# RL6955_IP_SVD register map
Vendor: Realtek
Registers are 32-bit, read-write, reset 0x0 unless marked. A register's access mark holds for its fields unless they carry their own. Offsets are from the block's base; [hi:lo] are bit positions; lines under a group give offsets from that group; {n}, {i} and the like mark numbered series; <NAME> marks a mode.

## PSRAM_REG (part 1 of 2)
Base 0x41909000
Same registers: SPI_FLASH_CTRL 0x4190B000
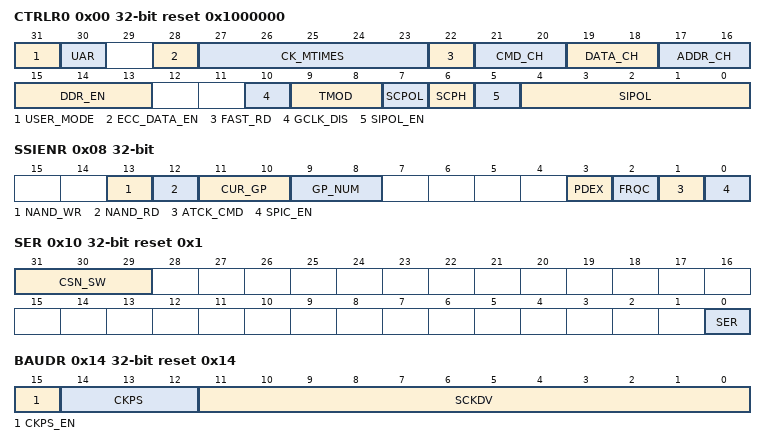
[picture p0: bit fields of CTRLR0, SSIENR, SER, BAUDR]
0x00 CTRLR0 reset 0x1000000 — Control Register 0
  [31] USER_MODE — User mode bit. Enable to enter user mode. Disable to enter auto mode. It can not be changed while SPIC is busy (28 [0] BUSY). 1: User mode. User can push data to FIFO and set SSIENR to 1. SPIC won't accept auto read/write command. 0: Auto mode. User can't push data to FIFO and set SSIENR to 1. SPIC will accept auto read/write command.
  [30] UAR — User mode bit auto reset. Enable to auto reset USER_MODE to 0 after current user mode transaction is over (SPIC_EN reset to 0).
  [28] ECC_DATA_EN — Indicate the data path should go through ECC in NAND user mode read write. ECC mode. User should program 0x170 and 0x174. The read/write data flow will go through ECC module. Normal mode. The read/write data flow will bypass ECC module. Exists: TAG >= 2.0.11. Available only if configuration of NAND_EN and ECC_EN are defined.
  [27:23] CK_MTIMES — Indicates the check times. If Flash is always busy in auto-check times, it causes ACEIR interrupt. The delay time (cycles) is related to bus_clk. The cycles of the parameter = (CK_MTIMES << (11+ATCK_BIT_EXTEND).). User should ensure the timeout > Write time of Flash The timeout time(ns) = 2*BAUDR*(1/SPIC_freq)(8/CH) (CK_MTIMES << (11+ATCK_BIT_EXTEND).) Example 1: Flash Program time= 1ms, BAUDR=1, CH=1 (SPI) and (1/SPIC_freq) = 10ns. ATCK_MTIMES should be to set 4. Example 2: SPIC_freq = 200MHz, BAUDR = 1, CH =4 (QSPI), and ATCK_BIT_EXTEND = 2, the maximum auto_check time should be = 2*1*(1/200MHz)(8/4) (5'b11111<<13) = 2*1*(1/200MHz)(8/4) (18'b11_1110_0000_0000_0000) = 2*1*(1/200MHz)(8/4) (18'h3_e000) = 2*1*(1/200MHz)(8/4) (253952) = 5079040 ns = 5.07 ms Suggestion: If ACEIR interrupt occurs, the user should check the flash status by the software itself. Note: Before SVN 8369 Version, CK_MTIMES is fixed to shift 10bit. The formula becomes 2*BAUDR*(1/SPIC_freq)(8/CH) (CK_MTIMES << (10))
  [22] FAST_RD — Indicates to use fast read command in user mode. If setting to 1, SPIC would use FBAUDR to generate spi_sclk.
  [21:20] CMD_CH — Indicates channel number of command phase in transmitting or receiving data. Command phase is usually used to send SPI command. 0: single channel 1: dual channels 2: quad channels 3: octal channel
  [19:18] DATA_CH — Indicates channel number of data phase in transmitting or receiving data. Data phase is used to send data after address phase. 0: single channel 1: dual channels 2: quad channels 3: octal channel
  [17:16] ADDR_CH — Indicates channel number of address phase after command phase. Addr phase is used to send address or data. Addr phase is between one-byte command and a data phase. The number of bytes is determined by the ADDR_LENGTH. 0: single channel 1: dual channels 2: quad channels 3: octal channel
  [15:13] DDR_EN — Indicates the DDR mode in CMD_CH/DATA_CH/ADDR_CH. CTRLR0[15]: CMD_CH (always 2-Byte CMD type) CTRLR0[14]: DATA_CH CTRLR0[13]: ADDR_CH 0: Disable 1: Enable Available only if configuration of DDR_EN is defined.
  [10] GCLK_DIS — Set to disable gated clock of icg cell
  [9:8] TMOD — Indicates transfer mode. 2'b00: transmit mode Others (or 2'b11): receive mode
  [7] SCPOL — Indicates serial clock polarity. It is used to select the polarity of the inactive serial clock. 0: inactive state of serial clock is low 1: inactive state of serial clock is high
  [6] SCPH — Indicates serial clock phase. The serial clock phase selects the relationship the serial clock with the slave select signal. 0: serial clock toggles in middle of first data bit 1: serial clock toggles at start of first data bit
  [5] SIPOL_EN — Set to enable SIPOL
  [4:0] SIPOL — While SIPOL_EN = 1 : SPI_CS is inactive state (SPI_CS ==1): spi_sin[3:0] = SIPOL[3:0] SPI_CS is active(SPI_CS ==0): spi_sin[3:1] = SIPOL[3:1] (single channel) spi_sin[3:2] = SIPOL[3:2] (dual channel) (SIPOL[4]: reserved for spi_in[7:4])
0x04 RX_NDF — Control Register 1
  [23:0] RX_NDF — Indicates a number of data frames (unit: Byte). When executing receives operation in user mode, SPIC receives data continuously until data frames are equal to RX_NDF.
0x08 SSIENR access per field — SPIC Enable Register
  [13] NAND_WR rw — Set to enable SPIC when start NAND auto command flow in user mode write transactions. To start NAND auto command flow user write transaction, please do not set SSIENR.SPIC_EN. If NAND_WR is activated, SPIC will send WEN command, Page Load program data command and Page execute command to NAND Flash. Write: 0 - Not to activate NAND auto command flow user write 1 - Activate NAND auto command flow user write Read: 0 - NAND auto command flow user write is done 1 - NAND auto command flow user write is still in progress
  [12] NAND_RD rw — Set to enable SPIC when start NAND auto command flow in user read transactions. To start NAND auto command flow user read transaction, please do not set SSIENR.SPIC_EN. If NAND_RD is activated, SPIC will send Page read data command and Read data command to NAND Flash. Write: 0 - Not to activate NAND auto command flow user read 1 - Activate NAND auto command flow user read Read: 0 - NAND auto command flow user read is done 1 - NAND auto command flow user read is still in progress
  [11:10] CUR_GP ro — Only used in frequency change function. Used to identify which group register data is internal used. When frqc_req and frqc_ack are both high, CUR_GP will switch to the group which in GP_NUM. Exists: TAG >= 1.0.4.
  [9:8] GP_NUM rw — Only used in frequency change function. Set to determine which group register user want to read or write. Base on different operation frequency, some control register setting will change. Therefore we build second group register on USER_LENGTH.USER_RD_DUMMY_LENGTH, AUTO_LENGTH.RD_DUMMY_LENGTH, AUTO_LENGTH.RDSR_DUMMY_LENGTH, AUTO_LENGTH.IN_PHYSICAL_CYC, TPR0.CS_TCEM, TPR0.CS_ACTIVE_HOLD, TPR0.CS_H_WR_DUM_LEN, TPR0.CS_H_RD_DUM_LEN, AUTO_LENGTH2.WR_DUMMY_LENGTH, TPR1.CR_TPWR, TPR1.CR_IDLE_WINDOW, TPR1.CS_ACTICE_SETUP. Exists: TAG >= 1.0.4.
  [3] PDEX rw — Set to trigger device enter sleep mode or deep power down mode. After setting PDEX_CTRL0, PDEX_CTRL1, PDEX_CTRL2 and TPR2, then set this bit to trigger PDEX flow. Write: 0 - Not to activate PDEX 1 - Activate PDEX Read: 0 - PDEX is still in progress 1 - PDEX is done Exists: TAG >= 2.0.5.
  [2] FRQC rw — Set to enable frequency change function. SPIC will chop current transaction and then set frqc_req = 1 after setting this bit. Frquency change is finished when frqc_req and frqc_ack are both high and then the choped transaction will return and continue. Write: 0: Not to activate FRQC 1: Activate FRQC Read: 0: FRQC is still in progress 1: FRQC is done Exists: TAG >= 1.0.4.
  [1] ATCK_CMD rw — Set to enable ATCK_CMD implementation. After setting SPIC would not accept any command until checking Flash is not busy or checking time out. (Use in User Mode, especially for Erase/Program to check status automatically.) If CTRLR2.SEQ_SET setting, this function needs to disable.
  [0] SPIC_EN rw — Set to enable SPIC and start user mode transaction. SPIC will reset SPIC_EN to 0 after user mode transaction is finished. SPIC_EN can only be set when BOOT_FIN=1 (boot finished) and USER_MODE=1 (user mode). (User can read SPIC_EN to check whether current user mode transaction is finished.)
0x10 SER reset 0x1 — Slave Enable Register
  [31:29] CSN_SW — Set to determine the switch of csn0 and csn1~3. 3'b000: no switch 3'b001: csn0 switch with cs1 3'b010: csn0 switch with cs2 3'b100: csn0 switch with cs3 Exists: TAG >= 2.0.8.
  [0] SER — Each bit in the register corresponds to one SPI Flash. In user mode user program the register to select target flash. 0: Not selected 1: Selected
0x14 BAUDR reset 0x14 — Baud Rate Select
  [15] CKPS_EN — CKPS enable bit. Set this bit to use CKPS feature. Exists: TAG >= 2.0.8.
  [14:12] CKPS — Indicate the shift range of device clk (SCLK) when CKPS_EN is set. (unit: bus_clk) Exists: TAG >= 2.0.8.
  [11:0] SCKDV — Define spi_sclk divider value. The frequency of spi_sclk is derived from: The frequency of spi_sclk = The frequency of bus_clk/(2*SCKDV).
0x18 TXFTLR — Transmit FIFO Threshold level
  [4:0] TFT — Transmit FIFO threshold. To Control FIFO entries of valid data in normal transfer except in receiving mode. When a number of FIFO entry is equal or smaller than TFT, SPIC triggers a spi_txeir interrupt. Ex: If TXFTLR = 5'h1, set spi_txeir when FIFO entries <= TFT (1)
0x1C RXFTLR reset 0x1F — Receive FIFO Threshold level
  [4:0] RFT — Receive FIFO threshold. To Control FIFO entries of valid data in receiving mode. When a number of FIFO entry is greater than RFT, SPIC triggers a spi_rxfir interrupt. Ex: If RXFTLR = 5'h1, set spi_rxfir when FIFO entries > RFT (1)
0x20 TXFLR ro — Transmit FIFO level Register
  [5:0] TXFLR — Transmit FIFO level. Indicates the FIFO entry level of valid data in normal mode except in receiving data. (or as FIFO_FLR in any mode)
0x24 RXFLR ro — Receive FIFO level Register
  [5:0] RXFLR — Receive FIFO level. Indicates the FIFO entries of valid data in receiving data.
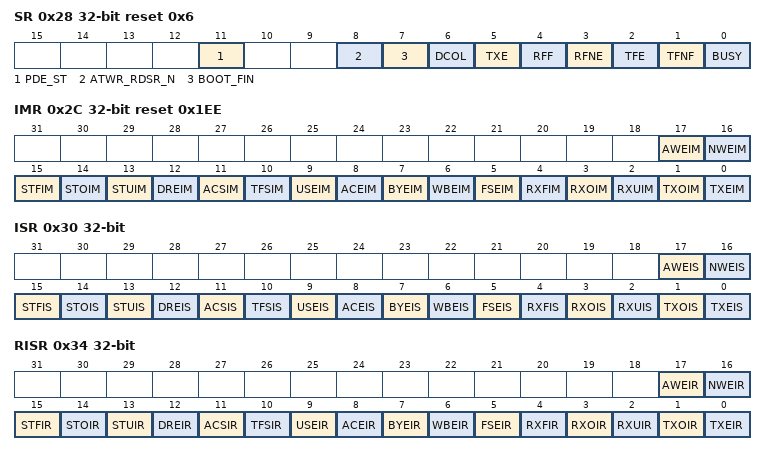
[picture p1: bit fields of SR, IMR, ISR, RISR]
0x28 SR access per field reset 0x6 — Status Register
  [11] PDE_ST ro — PDE state. Set if device has entered DPD/Sleep Mode Exists: TAG >= 2.0.7. Available only if configuration of SPI_PDEX_ENABLE is defined.
  [8] ATWR_RDSR_N rw — The previous auto write cmd didn't check the status register (RDSR). User should check the status register of Flash before next user mode transaction.
  [7] BOOT_FIN ro — Boot Finish. Set if count waiting cycles (Boot Delay Count) for SPI Flash becomes a stable state after power on (or system reset). 1: Boot Finish Note: Auto_mode would be blocked until boot finish. User cannot set CR until boot finish.
  [6] DCOL ro — Data Collision, or in Transmitting Status. 1: Status shows that SPIC is transmitting spi_flash_cmd/spi_flash_addr/spi_flash_data to SPI Flash. Suggest not reading DR during this transmitting state. (Check this status can avoid reading wrong data and cause SPIC error.)
  [5] TXE ro — Transmission error. Set if FIFO is empty and starting to transmit data to SPI Flash. This bit is cleared when read.
  [4] RFF ro — Receive FIFO full. Set if FIFO is full in receiving mode. This bit is cleared when read.
  [3] RFNE ro — Receive FIFO is not empty. Set if FIFO is not empty in receiving mode. This bit is cleared when read.
  [2] TFE ro — Transmit FIFO is empty. Set if FIFO is empty in transmit mode, else it is cleared when it has data in FIFO.
  [1] TFNF ro — Transmit FIFO is not full. Set if FIFO is not full in transmit mode, else it is cleared when FIFO is full.
  [0] BUSY ro — SPIC busy flag. Set if SPIC is still transmitting to or receiving data from SPI Flash, or TX_FIFO/RX_FIFO are not empty. User should check BUSY=0 before setting 0x00[31]USER_MODE.
0x2C IMR reset 0x1EE — Interrupt Mask Register
  [17] AWEIM — Nor Flash auto write error interrupt mask. 1: spi_aweir_r is not masked. 0: spi_aweir_r is masked. Exists: TAG >= 2.0.0.
  [16] NWEIM — NAND Flash write error interrupt mask. 1: spi_nweir_r is not masked. 0: spi_nweir_r is masked. Available only if configuration of NAND_EN is defined.
  [15] STFIM — Status FIFO full interrupt mask. 1: spi_stfir is not masked. 0: spi_stfir is masked. Available only if configuration of NAND_EN is defined.
  [14] STOIM — Status FIFO overflow interrupt masked. 1: spi_stoir_r is not masked. 0: spi_stoir_r is masked. Available only if configuration of NAND_EN is defined.
  [13] STUIM — Status FIFO underflow interrupt masked. 1: spi_stuir_r is not masked. 0: spi_stuir_r is masked. Available only if configuration of NAND_EN is defined.
  [12] DREIM — DR timeout error interrupt mask. 1: spi_dreir_r is not masked. 0: spi_dreir_r is masked.
  [11] ACSIM — Auto-check Flash Status raw interrupt mask. 1: spi_acsir_r is not masked. 0: spi_acsis_r is masked.
  [10] TFSIM — Transmit finish interrupt mask. 1: spi_tfsir_r is not masked. 0: spi_tfsir_r is masked.
  [9] USEIM — User_mode error interrupt mask. 1: spi_useir_r is not masked. 0: spi_useir_r is masked.
  [8] ACEIM — Auto-check timeout error interrupt mask. 1: spi_aceir_r is not masked. 0: spi_aceir_r is masked.
  [7] BYEIM — The Byte-Enable error interrupt mask. 1: spi_byeir_r is not masked. 0: spi_byeir_r is masked.
  [6] WBEIM — Write burst error interrupt mask. 1: spi_wbier_r is not masked. 0: spi_wbeir_r is masked.
  [5] FSEIM — FIFO size error interrupt mask. 1: spi_fseir_r is not masked. 0: spi_fseir _r is masked
  [4] RXFIM — Receive FIFO full interrupt mask. 1: spi_rxfir is not masked. 0: spi_rxfir is masked.
  [3] RXOIM — Receive FIFO overflow interrupt masked. 1: spi_rxoir_r is not masked. 0: spi_rxoir_r is masked.
  [2] RXUIM — Receive FIFO underflow interrupt masked. 1: spi_rxuir_r is not masked. 0: spi_rxuir_r is masked.
  [1] TXOIM — Transmit FIFO overflow interrupt mask. 1: spi_txoir_r is not masked. 0: spi_txoir_r is masked.
  [0] TXEIM — Transmit FIFO empty interrupt masked. 1: spi_txeir is not masked. 0: spi_txeir is masked.
0x30 ISR ro — Interrupt Status Register
  [17] AWEIS — Nor Flash auto write error interrupt status after masking. 1: spi_aweir_r is active after masking. 0: spi_aweir_r is not active after masking. Exists: TAG >= 2.0.0.
  [16] NWEIS — NAND Flash write error interrupt status raw interrupt status after masking. 1: spi_nweir_r is active after masking. 0: spi_nweir_r is not active after masking. Available only if configuration of NAND_EN is defined.
  [15] STFIS — Status FIFO full raw interrupt status after masking. 1: spi_stfir_r is active after masking. 0: spi_stfir_r is not active after masking. Available only if configuration of NAND_EN is defined.
  [14] STOIS — Status FIFO overflow interrupt status after masking. 1: spi_stoir_r is active after masking. 0: spi_stoir_r is not active after masking. Available only if configuration of NAND_EN is defined.
  [13] STUIS — Status FIFO underflows interrupt status after masking. 1: spi_stuir_r is active after masking. 0: spi_stuir_r is not active after masking. Available only if configuration of NAND_EN is defined.
  [12] DREIS — DR timeout error status after masking. 1: spi_dreir_r is active after masking. 0: spi_dreir_r is not active after masking.
  [11] ACSIS — Auto-check Flash Status after masking. 1: spi_aceir_r is active after masking. 0: spi_aceir_r is not active after masking.
  [10] TFSIS — Transmit finish interrupt status after masking. 1: spi_tfsir_r is active after masking. 0: spi_tfsir_r is not active after masking.
  [9] USEIS — User mode error status after masking. 1: spi_useir_r is active after masking. 0: spi_useir_r is not active after masking.
  [8] ACEIS — Auto-check timeout error status after masking. 1: spi_aceir_r is active after masking. 0: spi_aceir_r is not active after masking.
  [7] BYEIS — The byte-Enable error interrupts status after masking. 1: spi_byeir_r is active after masking. 0: spi_byeir_r is not active after masking.
  [6] WBEIS — Write burst error interrupt status after masking. 1: spi_wbeir_r is active after masking. 0: spi_wbeir_r is not active after masking.
  [5] FSEIS — FIFO size error interrupts status after masking. 1: spi_fesir_r is active after masking. 0: spi_fesir_r is not active after masking.
  [4] RXFIS — Receive FIFO full interrupt status after masking 1: spi_rxfir is active after masking. 0: spi_rxfir is not active after masking.
  [3] RXOIS — Receive FIFO overflow interrupt status after masking. 1: spi_rxoir_r is active after masking. 0: spi_rxoir_r is not active after masking.
  [2] RXUIS — Receive FIFO underflows interrupt status after masking. 1: spi_rxuir_r is active after masking. 0: spi_rxuir_r is not active after masking.
  [1] TXOIS — Transmit FIFO overflow raw interrupt status after masking. 1: spi_txoir_r is active after masking. 0: spi_txoir_r is not active after masking.
  [0] TXEIS — Transmit FIFO empty raw interrupt status after masking. 1: spi_txeir is active after masking. 0: spi_txeir is not active after masking.
0x34 RISR ro — Raw Interrupt Status Register
  [17] AWEIR — Nor Flash auto write error interrupt status prior to masking. 1: spi_aweir_r is active prior to masking. 0: spi_aweir_r is not active prior to masking. Exists: TAG >= 2.0.0.
  [16] NWEIR — NAND Flash write error interrupt status raw interrupt status prior to masking. 1: spi_nweir_r is active prior to masking. 0: spi_nweir_r is not active prior to masking. Note: Available only if configuration of NAND_EN is defined.
  [15] STFIR — Status FIFO full raw interrupt status prior to masking 1: spi_stfir is active prior to masking. 0: spi_stfir is not active prior to masking. Note: Available only if configuration of NAND_EN is defined.
  [14] STOIR — Status FIFO overflows raw interrupt status prior to masking. 1: spi_stoir_r is active prior to masking. 0: spi_stoir_r is not active prior to masking. Note: Available only if configuration of NAND_EN is defined.
  [13] STUIR — Status FIFO underflows raw interrupt status prior to masking. 1: spi_stuir_r is active prior to masking. 0: spi_stuir_r is not active prior to masking. Note: Available only if configuration of NAND_EN is defined.
  [12] DREIR — DR Timeout error status raw interrupt status prior to masking 1: spi_dreir_r is active prior to masking. 0: spi_dreir_r is not active prior to masking.
  [11] ACSIR — Auto-check Flash Status raw interrupt status prior to masking 1: spi_acsir_r is active prior to masking. 0: spi_acsir_r is not active prior to masking.
  [10] TFSIR — Transmit Finish Status raw interrupt status prior to masking 1: spi_tfsir_r is active prior to masking. 0: spi_tfsir_r is not active prior to masking.
  [9] USEIR — User_mode error status raw interrupt status prior to masking 1: spi_useir_r is active prior to masking. 0: spi_useir_r is not active prior to masking.
  [8] ACEIR — Auto-check timeout error status raw interrupt status prior to masking 1: spi_aceir_r is active prior to masking. 0: spi_aceir_r is not active prior to masking.
  [7] BYEIR — The Byte-Enable error interrupt status raw interrupt status prior to mask. 1: spi_byeir_r is active prior to masking. 0: spi_byeir_r is not active prior to masking.
  [6] WBEIR — Write burst error interrupt status raw interrupt status prior to masking. 1: spi_wbeir_r is active prior to masking. 0: spi_wbeir_r is not active prior to masking.
  [5] FSEIR — FIFO size error interrupt status raw interrupt status prior to masking. 1: spi_fseir_r is active prior to masking. 0: spi_fseir _r is not active prior to masking.
  [4] RXFIR — Receive FIFO full raw interrupt status prior to masking 1:spi_rxfir is active prior to masking. 0: spi_rxfir is not active prior to masking.
  [3] RXOIR — Receive FIFO overflows raw interrupt status prior to masking. 1: spi_rxoir_r is active prior to masking. 0: spi_rxoir_r is not active prior to masking.
  [2] RXUIR — Receive FIFO underflows raw interrupt status prior to masking. 1: spi_rxuir_r is active prior to masking. 0: spi_rxuir_r is not active prior to masking.
  [1] TXOIR — Transmit FIFO overflow raw interrupt status prior to masking. 1: spi_txoir_r is active prior to masking. 0: spi_txoir_r is not active prior to masking.
  [0] TXEIR — Transmit FIFO empty raw interrupt status prior to masking. 1: spi_txeir is active prior to masking. 0: spi_txeir is not active prior to masking.
0x38 TXOICR — Transmit FIFO Overflow Interrupt Clear Register
  [0] TXOICR — When reading/writing the register, spi_rxoir_r would be cleared. Note: Only response value 0 when read.
0x3C RXOICR — Receive FIFO Overflow Interrupt Clear Register
  [0] RXOICR — When reading/writing the register, spi_rxoir_r would be cleared. Note: Only response value 0 when read.
0x40 RXUICR — Receive FIFO Underflow Interrupt Clear Register
  [0] RXUICR — When reading/writing the register, spi_rxuir_r would be cleared. Note: Only response value 0 when read.
0x44 MSTICR — Master error Interrupt Clear Register
  [0] MSTICR — When reading/writing the register, spi_mstir_r would be cleared. Note: Only response value 0 when read.
0x48 ICR — Interrupt Clear Register
  [0] ICR — When reading/writing the register, all interrupt would be cleared. Note: Only response value 0 when read.
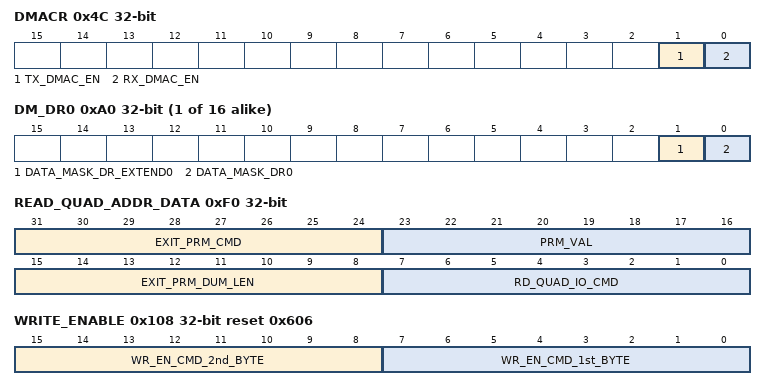
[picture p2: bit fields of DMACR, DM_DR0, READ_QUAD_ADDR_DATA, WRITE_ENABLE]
0x4C DMACR — DMA Control Register
  [1] TX_DMAC_EN — Transmit DMA Enable. This bit enables/disables the transmit FIFO DMA channel. 0: Transmit DMA disabled 1: Transmit DMA enabled
  [0] RX_DMAC_EN — Receive DMA Enable. This bit enables/disables the receive FIFO DMA channel 0: Receive DMA disabled 1: Receive DMA enabled
0x50 DMATDLR — DMA Transmit Data Level Register
  [4:0] DMATDL — Transmit Data Level. This bit field controls the level at which a DMA request is made by the transmit logic. It is equal to the watermark level; that is, the dma_tx_req signal is generated when the number of valid data entries in the transmit FIFO is equal to or below this field value, and TDMAE = 1.
0x54 DMARDLR — DMA Receive Data Level Register
  [4:0] DMARDL — Receive Data Level. This bit field controls the level at which a DMA request is made by the receive logic. The watermark level = DMARDL+1; that is, dma_rx_req is generated when the number of valid data entries in the receive FIFO is equal to or above this field value + 1, and RDMAE=1.
0x58 IDR ro reset 0x400FF01 — Identification Register
  [31:0] IDCODE — Contain the decimal value of SPIC version.
0x5C SPIC_VERSION ro — SPIC version ID Register
  [31:0] SPIC_VERSION — Contain the decimal value of SPIC version. (After 201612: SVN_NUM changes to Git Counter)
{0x60+4i} DR{i} (i=0..15) — Data Register {i}
  [31:0] DR{i} — It is a data buffer with 8-bit width FIFO. If accessing in word data byte, it would read/write 4 entries of FIFO. SPIC will set SSIENR.SPIC_EN=1 automatically if user continues to push DR when DR is full in user write mode.
{0xA0+4i} DM_DR{i} wo (i=0..15) — Data Mask Data Register {i}
  [1] DATA_MASK_DR_EXTEND{i} — It is a extended data buffer for spi_dm[1] signal in user mode when the width of spi_dm is 2-bit (DQ16). The output value of spi_dm[1] is the data that has been pushed to DM_FIFO [1]. If DM_FIFO is empty, the output value of spi_data_en will be (~DM_ACT). Available only if configuration of DM_EN and DQ16 are defined.
  [0] DATA_MASK_DR{i} — It is a data buffer for spi_dm signal in user mode. The output value of spi_dm is the data that has been pushed to DM_FIFO [0]. If DM_FIFO is empty, the output value of spi_data_en will be (~DM_ACT). Available only if configuration of DM_EN are defined.
0xE0 READ_FAST_SINGLE — Fast Read Data Command of SPI Flash
  [15:0] FRD_CMD — Indicate SPI Flash command value of fast read command. The baud rate is used with FBAUDR. FRD_CMD[15:8] is for RD_OCTA_IO_CMD_2nd_BYTE (only available when configuration of DDR_EN is defined) FRD_CMD[7:0] is for RD_OCTA_IO_CMD_1st_BYTE
0xE4 READ_DUAL_DATA — Dual Output Read Command of SPI Flash
  [7:0] RD_DUAL_O_CMD — Indicates SPI Flash command value of dual data read command.
0xE8 READ_DUAL_ADDR_DATA — Dual I/O Read Command of SPI Flash
  [7:0] RD_DUAL_IO_CMD — Indicates SPI Flash command value of dual address and data read command.
0xEC READ_QUAD_DATA — Qaud Output Read Command of SPI Flash
  [7:0] RD_QUAD_O_CMD — Indicates SPI Flash command value of quad data read command.
0xF0 READ_QUAD_ADDR_DATA — Quad I/O Read Command of SPI Flash
  [31:24] EXIT_PRM_CMD — Exit High Performance Read Mode commend. Note: Available only if configuration of PRM_EN is defined (SPIC Lite ver).
  [23:16] PRM_VAL — High Performance Read Mode Value. Note: Available only if configuration of PRM_EN is defined (SPIC Lite ver).
  [15:8] EXIT_PRM_DUM_LEN — If Exit PRM commend is more than 1 byte, use EXIT_PRM_DUM_LEN to extend the commend. It is referenced by bus_clk. Ex. In qpi mode (4-4-4), FFFFFFFFh data cycle should be issued (4-byte data in 8 spi cycles). EXIT_PRM_CMD only push 1 byte (2 spi cycles), so use EXIT_PRM_DUM_LEN to extend 6 spi cycles. EXIT_PRM_DUM_LEN = 6 (spi_cycle) * (2 * baurd_rate) Note: Available only if configuration of PRM_EN is defined (SPIC Lite ver).
  [7:0] RD_QUAD_IO_CMD — Indicates SPI Flash command value of quad address and data read command.
0xF4 WRITE_SIGNLE reset 0xCA — Page Program Command of SPI Flash
  [15:0] WR_CMD — Indicate SPI Flash command value of write command. WR_CMD[15:8] is for WR_OCTA_IO_CMD_2nd_BYTE (only available when configuration of DDR_EN is defined) WR_CMD[7:0] is for WR_OCTA_IO_CMD_1st_BYTE
0xF8 WRITE_DUAL_DATA — Dual Data Input Program Command of SPI Flash
  [7:0] WR_DUAL_I_CMD — Indicates SPI Flash command value of dual data write command.
0xFC WRITE_DUAL_ADDR_DATA — Dual Address and Data Output Read Command of SPI Flash
  [7:0] WR_DUAL_II_CMD — Indicates SPI Flash command value of dual address and data write command.
0x100 WRITE_QUAD_DATA reset 0x20 — Quad Data Input Program Command of SPI Flash
  [7:0] WR_QUAD_I_CMD — Indicates SPI Flash command value of quad data write command.
0x104 WRITE_QUAD_ADDR_DATA reset 0x26 — Quad Address and Data Output Read Command of SPI Flash
  [7:0] WR_QUAD_II_CMD — Indicates SPI Flash command value of quad address and data write command.
0x108 WRITE_ENABLE reset 0x606 — Write Enable Command of SPI Flash
  [15:8] WR_EN_CMD_2nd_BYTE — Indicates SPI Flash command value of 2nd byte of write enable. Available only if configuration of DDR_EN is defined.
  [7:0] WR_EN_CMD_1st_BYTE — Indicates SPI Flash command value of 1st byte of write enable.
